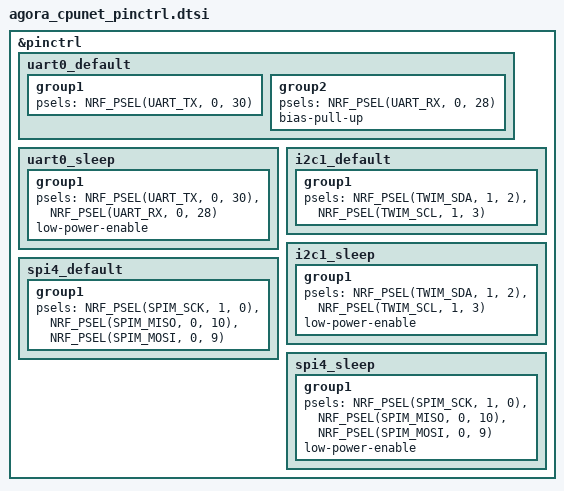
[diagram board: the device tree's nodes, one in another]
&pinctrl {
	uart0_default: uart0_default {
		group1 {
			psels = <NRF_PSEL(UART_TX, 0, 30)>;
		};
		group2 {
			psels = <NRF_PSEL(UART_RX, 0, 28)>;
			bias-pull-up;
		};
	};

	uart0_sleep: uart0_sleep {
		group1 {
			psels = <NRF_PSEL(UART_TX, 0, 30)>,
				<NRF_PSEL(UART_RX, 0, 28)>;
			low-power-enable;
		};
	};

	i2c1_default: i2c1_default {
		group1 {
			psels = <NRF_PSEL(TWIM_SDA, 1, 2)>,
				<NRF_PSEL(TWIM_SCL, 1, 3)>;
		};
	};

	i2c1_sleep: i2c1_sleep {
		group1 {
			psels = <NRF_PSEL(TWIM_SDA, 1, 2)>,
				<NRF_PSEL(TWIM_SCL, 1, 3)>;
			low-power-enable;
		};
	};

	spi4_default: spi4_default {
		group1 {
			psels = <NRF_PSEL(SPIM_SCK, 1, 0)>,
				<NRF_PSEL(SPIM_MISO, 0, 10)>,
				<NRF_PSEL(SPIM_MOSI, 0, 9)>;
		};
	};

	spi4_sleep: spi4_sleep {
		group1 {
			psels = <NRF_PSEL(SPIM_SCK, 1, 0)>,
				<NRF_PSEL(SPIM_MISO, 0, 10)>,
				<NRF_PSEL(SPIM_MOSI, 0, 9)>;
			low-power-enable;
		};
	};
};
